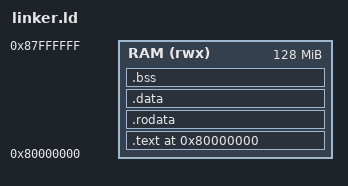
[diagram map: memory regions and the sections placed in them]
ENTRY(_start)

MEMORY
{
    RAM (rwx) : ORIGIN = 0x80000000, LENGTH = 128M
}

SECTIONS
{
    . = ORIGIN(RAM);

    .text : ALIGN(4) {
        KEEP(*(.text.start))
        *(.text .text.*)
    } > RAM

    .rodata : ALIGN(8) {
        *(.rodata .rodata.*)
    } > RAM

    .data : ALIGN(8) {
        *(.data .data.*)
    } > RAM

    .bss : ALIGN(8) {
        __bss_start = .;
        *(.bss .bss.*)
        *(COMMON)
        __bss_end = .;
    } > RAM

    . = ALIGN(16);
    . += 16K;
    _stack_top = .;
}
